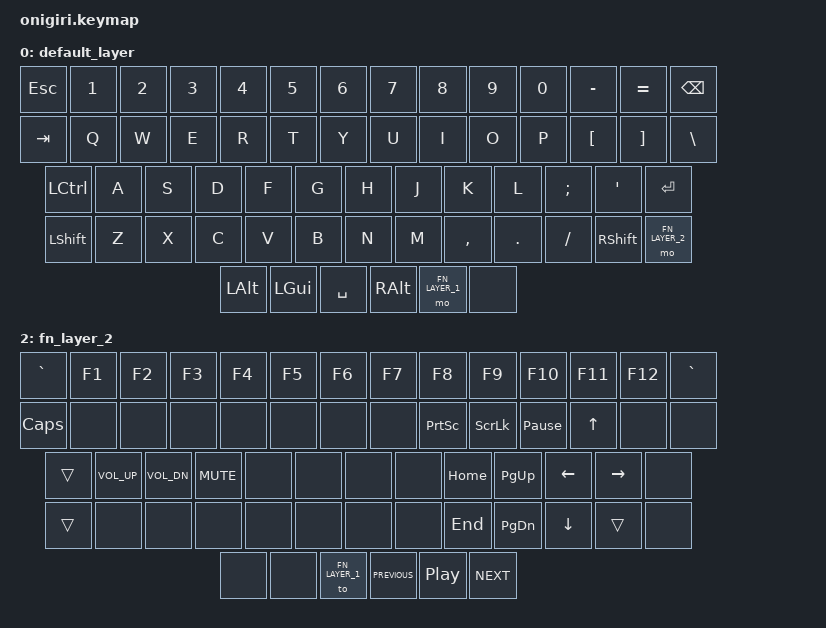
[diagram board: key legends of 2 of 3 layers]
/**
 * Copyright (c) 2024 Kuba Birecki
 *
 * SPDX-License-Identifier: MIT
 */

#include <behaviors.dtsi>
#include <dt-bindings/zmk/bt.h>
#include <dt-bindings/zmk/rgb_fx.h>
#include <dt-bindings/zmk/keys.h>
#include <dt-bindings/zmk/outputs.h>

#define DEFAULT_LAYER 0
#define FN_LAYER_1 1
#define FN_LAYER_2 2

/ {
    keymap {
        compatible = "zmk,keymap";

        default_layer {
            // ┏━━━━━━━━━━━━━━━━━━━━━━━━━━━━━━━━━━━━━━━━━━━━━━━━━━━━━━━━━━━━━━━━━━━━┓
            // ┃ ESC | 1 | 2 | 3 | 4 | 5 | 6 | 7 | 8 | 9 | 0 | - | = |     BSPC     ┃
            // ┃  TAB  | Q | W | E | R | T | Y | U | I | O | P | [ | ] |    \       ┃
            // ┃  CTRL  | A | S | D | F | G | H | J | K | L | ; | ' |      ENTER    ┃
            // ┃  SHIFT   | Z | X | C | V | B | N | M | , | . | / |   SHIFT   | FN3 ┃
            // ┗━━━━━━┓ OPT | CMD |           SPACE         | ALT | FN1 | FN2 ┏━━━━━┛
            //        ┗━━━━━━━━━━━━━━━━━━━━━━━━━━━━━━━━━━━━━━━━━━━━━━━━━━━━━━━┛

            bindings = <
                &kp ESC &kp N1 &kp N2 &kp N3 &kp N4 &kp N5 &kp N6 &kp N7 &kp N8 &kp N9 &kp N0 &kp MINUS &kp EQUAL &kp BSPC
                &kp TAB &kp Q &kp W &kp E &kp R &kp T &kp Y &kp U &kp I &kp O &kp P &kp LBKT &kp RBKT &kp BSLH
                &kp LCTRL &kp A &kp S &kp D &kp F &kp G &kp H &kp J &kp K &kp L &kp SEMI &kp SQT &kp ENTER
                &kp LSHFT &kp Z &kp X &kp C &kp V &kp B &kp N &kp M &kp COMMA &kp DOT &kp SLASH &kp RSHFT &mo FN_LAYER_2
                &kp LALT &kp LGUI &kp SPACE &kp RALT &mo FN_LAYER_1 &none
            >;
        };

        fn_layer_1 {
            // Utility layer
            //
            // ┏━━━━━━━━━━━━━━━━━━━━━━━━━━━━━━━━━━━━━━━━━━━━━━━━━━━━━━━━━━━━━━━━━━━━┓
            // ┃     |BT1|BT2|BT3|   |   |   |   |   |   |   |   |   |   DEFAULT    ┃
            // ┃OUT_TOG|CLR|   |   |   |   |   |   | c | < | > |   |   |            ┃
            // ┃        |   |   |   |   |   |   |   |   |   |   |   |               ┃
            // ┃          |   |   |   |   |   |   |   |   |   |   |           |     ┃
            // ┗━━━━━━┓     |     |                         |     |     |     ┏━━━━━┛
            //        ┗━━━━━━━━━━━━━━━━━━━━━━━━━━━━━━━━━━━━━━━━━━━━━━━━━━━━━━━┛

            bindings = <
                &none &bt BT_SEL 0  &bt BT_SEL 1 &bt BT_SEL 2 &none &none &none &none &none &none &none &none &none &to DEFAULT_LAYER
                &out OUT_TOG &bt BT_CLR &none &none &none &none &none &none &rgbfx RGBFX_TOGGLE(0) &rgbfx RGBFX_NEXT(0) &rgbfx RGBFX_PREVIOUS(0) &none &none &none
                &none &none &none &none &none &none &none &none &none &none &none &none &none
                &none &none &none &none &none &none &none &none &none &none &none &none &none
                &sys_reset &bootloader &none &none &none &none
            >;
        };

        fn_layer_2 {
            // Defualt HHKB Function Layer Bindings
            //
            // ┏━━━━━━━━━━━━━━━━━━━━━━━━━━━━━━━━━━━━━━━━━━━━━━━━━━━━━━━━━━━━━━━━━━━━┓
            // ┃ ` | F1 | F2 | F3 | F4 | F5 | F6 | F7 | F8 | F9 | F10 | F11 | F12 | ┃
            // ┃       |   |   |   |   |   |   |   | c | < | > | ▲ |   |            ┃
            // ┃        |VUP|VDN|MUT|   |   |   |   | ⇤ | ↗ | ◄ | ► |               ┃
            // ┃          |   |   |   |   |   |   |   | ⇥ | ↘ | ▼ |           |     ┃
            // ┗━━━━━━┓     |     |           UTIL          |     | PPS |     ┏━━━━━┛
            //        ┗━━━━━━━━━━━━━━━━━━━━━━━━━━━━━━━━━━━━━━━━━━━━━━━━━━━━━━━┛

            bindings = <
                &kp GRAVE &kp F1 &kp F2 &kp F3 &kp F4 &kp F5 &kp F6 &kp F7 &kp F8 &kp F9 &kp F10 &kp F11 &kp F12 &kp GRAVE
                &kp CAPS &none &none &none &none &none &none &none &kp PSCRN &kp SLCK &kp PAUSE_BREAK &kp UP &none &none
                &trans &kp C_VOL_UP &kp C_VOL_DN &kp K_MUTE &none &none &none &none &kp HOME &kp PG_UP &kp LEFT &kp RIGHT &none
                &trans &none &none &none &none &none &none &none &kp END &kp PG_DN &kp DOWN &trans &none
                &none &none &to FN_LAYER_1 &kp C_PREVIOUS &kp C_PLAY_PAUSE &kp C_NEXT
            >;
        };
    };
};
